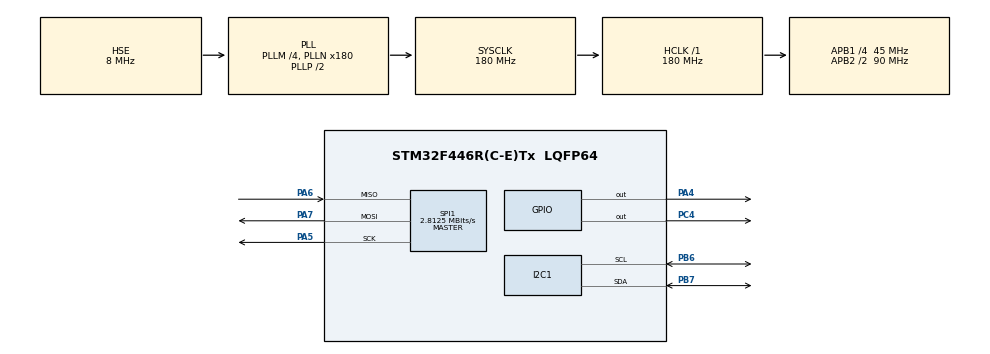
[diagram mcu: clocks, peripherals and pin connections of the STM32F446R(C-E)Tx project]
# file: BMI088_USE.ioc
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Mcu.Family=STM32F4
Mcu.Name=STM32F446R(C-E)Tx
Mcu.Package=LQFP64
NVIC.PriorityGroup=NVIC_PRIORITYGROUP_4
PA13.Mode=Serial_Wire
PA13.Signal=SYS_JTMS-SWDIO
PA14.Mode=Serial_Wire
PA14.Signal=SYS_JTCK-SWCLK
PA4.PinState=GPIO_PIN_SET
PA4.Signal=GPIO_Output
PA5.Mode=Full_Duplex_Master
PA5.Signal=SPI1_SCK
PA6.Mode=Full_Duplex_Master
PA6.Signal=SPI1_MISO
PA7.Mode=Full_Duplex_Master
PA7.Signal=SPI1_MOSI
PB6.Mode=I2C
PB6.Signal=I2C1_SCL
PB7.Mode=I2C
PB7.Signal=I2C1_SDA
PC14-OSC32_IN.Mode=LSE-External-Oscillator
PC14-OSC32_IN.Signal=RCC_OSC32_IN
PC15-OSC32_OUT.Mode=LSE-External-Oscillator
PC15-OSC32_OUT.Signal=RCC_OSC32_OUT
PC4.PinState=GPIO_PIN_SET
PC4.Signal=GPIO_Output
PH0-OSC_IN.Mode=HSE-External-Oscillator
PH0-OSC_IN.Signal=RCC_OSC_IN
PH1-OSC_OUT.Mode=HSE-External-Oscillator
PH1-OSC_OUT.Signal=RCC_OSC_OUT
ProjectManager.HeapSize=0x200
ProjectManager.StackSize=0x400
ProjectManager.TargetToolchain=MDK-ARM V5.32
RCC.AHBFreq_Value=180000000
RCC.APB1CLKDivider=RCC_HCLK_DIV4
RCC.APB1Freq_Value=45000000
RCC.APB1TimFreq_Value=90000000
RCC.APB2CLKDivider=RCC_HCLK_DIV2
RCC.APB2Freq_Value=90000000
RCC.APB2TimFreq_Value=180000000
RCC.CortexFreq_Value=180000000
RCC.HCLKFreq_Value=180000000
RCC.HSE_VALUE=8000000
RCC.PLLM=4
RCC.PLLN=180
RCC.PLLSourceVirtual=RCC_PLLSOURCE_HSE
RCC.SYSCLKFreq_VALUE=180000000
RCC.SYSCLKSource=RCC_SYSCLKSOURCE_PLLCLK
RCC.USBFreq_Value=180000000
RCC.VCOOutputFreq_Value=360000000
SPI1.BaudRatePrescaler=SPI_BAUDRATEPRESCALER_32
SPI1.CLKPhase=SPI_PHASE_2EDGE
SPI1.CLKPolarity=SPI_POLARITY_HIGH
SPI1.CalculateBaudRate=2.8125 MBits/s
SPI1.Direction=SPI_DIRECTION_2LINES
SPI1.Mode=SPI_MODE_MASTER
SPI1.VirtualType=VM_MASTER
board=custom

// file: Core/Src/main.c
/* USER CODE BEGIN Header */
/**
  ******************************************************************************
  * @file           : main.c
  * @brief          : Main program body
  ******************************************************************************
  * @attention
  *
  * Copyright (c) 2024 STMicroelectronics.
  * All rights reserved.
  *
  * This software is licensed under terms that can be found in the LICENSE file
  * in the root directory of this software component.
  * If no LICENSE file comes with this software, it is provided AS-IS.
  *
  ******************************************************************************
  */
/* USER CODE END Header */
#include "main.h"
#include "i2c.h"
#include "spi.h"
#include "gpio.h"

/* USER CODE BEGIN Includes */
#include "bmi088.h"
#include <math.h>
#include "bmi088reg.h"
#include "qmc5883l.h"
#include "MahonyAHRS.h"
//#include "ZiTai-jiesuan.h"

/* USER CODE END Includes */

void SystemClock_Config(void);

/* USER CODE BEGIN 0 */
  acc_raw_data_t acc_data;
  gyro_raw_data_t gyro_raw_data;
//  qmc5883l_raw_data_t qmc5883l_raw_data;
  zitai_angle zitai;
  float x, y, z;
/* USER CODE END 0 */

int main(void)
{

  /* MCU Configuration--------------------------------------------------------*/

  /* Reset of all peripherals, Initializes the Flash interface and the Systick. */
  HAL_Init();

  /* Configure the system clock */
  SystemClock_Config();

  /* Initialize all configured peripherals */
  MX_GPIO_Init();
  MX_SPI1_Init();
  MX_I2C1_Init();
  /* USER CODE BEGIN 2 */
  BMI088_CONF_INIT();
  QMC5883L_Init();

  /* USER CODE END 2 */

  /* Infinite loop */
  while (1)
  {

    /* USER CODE BEGIN 3 */
//   QMC5883L_ReadDATA(&qmc5883l_raw_data);
     Read_Sensors(&acc_data, &gyro_raw_data,&x,&y,&z);
	 Calculate_Angles(&zitai.roll, &zitai.pitch, &zitai.yaw);

  }

  /* USER CODE END 3 */
}

void SystemClock_Config(void)
{
  RCC_OscInitTypeDef RCC_OscInitStruct = {0};
  RCC_ClkInitTypeDef RCC_ClkInitStruct = {0};

  /** Configure the main internal regulator output voltage
  */
  __HAL_RCC_PWR_CLK_ENABLE();
  __HAL_PWR_VOLTAGESCALING_CONFIG(PWR_REGULATOR_VOLTAGE_SCALE1);

  /** Initializes the RCC Oscillators according to the specified parameters
  * in the RCC_OscInitTypeDef structure.
  */
  RCC_OscInitStruct.OscillatorType = RCC_OSCILLATORTYPE_HSE;
  RCC_OscInitStruct.HSEState = RCC_HSE_ON;
  RCC_OscInitStruct.PLL.PLLState = RCC_PLL_ON;
  RCC_OscInitStruct.PLL.PLLSource = RCC_PLLSOURCE_HSE;
  RCC_OscInitStruct.PLL.PLLM = 4;
  RCC_OscInitStruct.PLL.PLLN = 180;
  RCC_OscInitStruct.PLL.PLLP = RCC_PLLP_DIV2;
  RCC_OscInitStruct.PLL.PLLQ = 2;
  RCC_OscInitStruct.PLL.PLLR = 2;
  if (HAL_RCC_OscConfig(&RCC_OscInitStruct) != HAL_OK)
  {
    Error_Handler();
  }

  /** Activate the Over-Drive mode
  */
  if (HAL_PWREx_EnableOverDrive() != HAL_OK)
  {
    Error_Handler();
  }

  /** Initializes the CPU, AHB and APB buses clocks
  */
  RCC_ClkInitStruct.ClockType = RCC_CLOCKTYPE_HCLK|RCC_CLOCKTYPE_SYSCLK
                              |RCC_CLOCKTYPE_PCLK1|RCC_CLOCKTYPE_PCLK2;
  RCC_ClkInitStruct.SYSCLKSource = RCC_SYSCLKSOURCE_PLLCLK;
  RCC_ClkInitStruct.AHBCLKDivider = RCC_SYSCLK_DIV1;
  RCC_ClkInitStruct.APB1CLKDivider = RCC_HCLK_DIV4;
  RCC_ClkInitStruct.APB2CLKDivider = RCC_HCLK_DIV2;

  if (HAL_RCC_ClockConfig(&RCC_ClkInitStruct, FLASH_LATENCY_5) != HAL_OK)
  {
    Error_Handler();
  }
}

void Error_Handler(void)
{
  __disable_irq();
  while (1)
  {
  }
}
